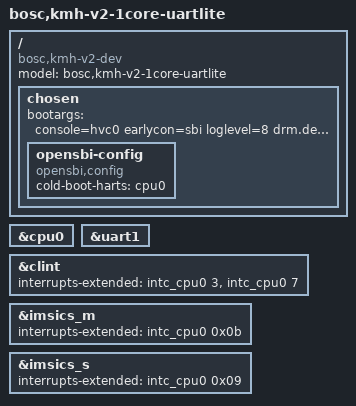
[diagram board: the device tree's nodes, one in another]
// SPDX-License-Identifier: (GPL-2.0 OR MIT)
/* Copyright (c) 2023-2024 BOSC */

/dts-v1/;
#include "kmh-v2.dtsi"

/ {
	#address-cells = <2>;
	#size-cells = <2>;
	compatible = "bosc,kmh-v2-dev", "bosc,kmh-v2-soc";
	model = "bosc,kmh-v2-1core-uartlite";

	chosen {
		bootargs = "console=hvc0 earlycon=sbi loglevel=8 drm.debug=0x2 task=0x0000000000 guest_task=0x0000000000";
		opensbi-config {
		    compatible = "opensbi,config";
		    cold-boot-harts = <&cpu0>;
		};
	};
};

&cpu0 {
	status = "okay";
};

&uart1 {
	status = "okay";
};

&clint {
	interrupts-extended =
		<&intc_cpu0 3>, <&intc_cpu0 7>;
};

&imsics_m {
	interrupts-extended =
		<&intc_cpu0 0x0b>;
};

&imsics_s {
	interrupts-extended =
		<&intc_cpu0 0x09>;
};
